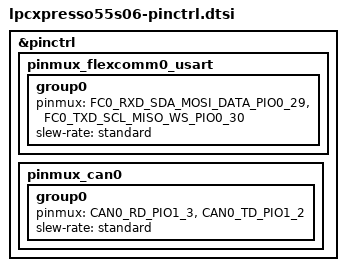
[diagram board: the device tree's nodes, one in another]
/*
 * NOTE: File generated by gen_board_pinctrl.py
 * from LPCXpresso55S06.mex
 *
 * Copyright 2022 NXP
 * SPDX-License-Identifier: Apache-2.0
 */


#include <nxp/lpc/LPC55S06JBD64-pinctrl.h>

&pinctrl {
	pinmux_flexcomm0_usart: pinmux_flexcomm0_usart {
		group0 {
			pinmux = <FC0_RXD_SDA_MOSI_DATA_PIO0_29>,
				<FC0_TXD_SCL_MISO_WS_PIO0_30>;
			slew-rate = "standard";
		};
	};

	pinmux_can0: pinmux_can0 {
		group0 {
			pinmux = <CAN0_RD_PIO1_3>,
				<CAN0_TD_PIO1_2>;
			slew-rate = "standard";
		};
	};

};
